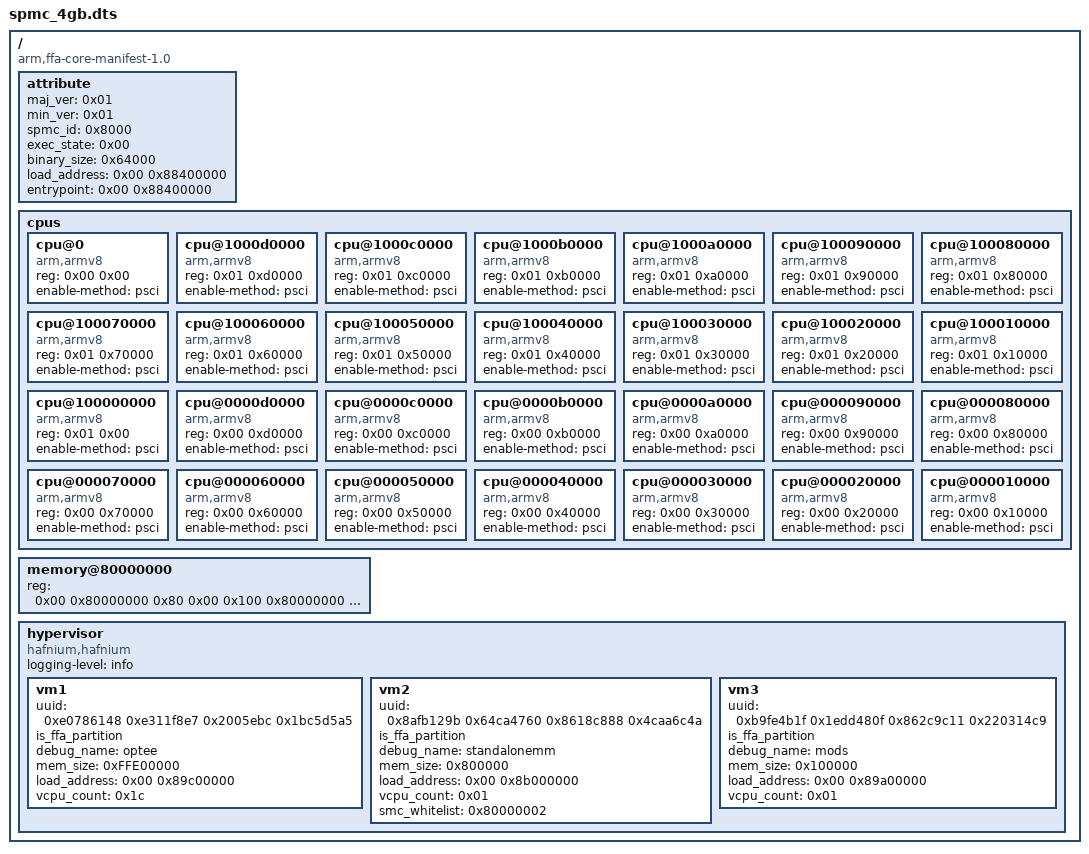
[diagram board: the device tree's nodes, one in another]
/dts-v1/;

/ {
	#size-cells = <0x02>;
	#address-cells = <0x02>;
	compatible = "arm,ffa-core-manifest-1.0";

	attribute {
		maj_ver = <0x01>;
		min_ver = <0x01>;
		spmc_id = <0x8000>;
		exec_state = <0x00>;
		binary_size = <0x64000>;
		load_address = <0x00 0x88400000>;
		entrypoint = <0x00 0x88400000>;
	};

	cpus {
		#address-cells = <0x02>;
		#size-cells = <0x00>;

		cpu@0 {
			device_type = "cpu";
			compatible = "arm,armv8";
			reg = <0x00 0x00>;
			enable-method = "psci";
		};

		cpu@1000d0000 {
			device_type = "cpu";
			compatible = "arm,armv8";
			reg = <0x01 0xd0000>;
			enable-method = "psci";
		};

		cpu@1000c0000 {
			device_type = "cpu";
			compatible = "arm,armv8";
			reg = <0x01 0xc0000>;
			enable-method = "psci";
		};

		cpu@1000b0000 {
			device_type = "cpu";
			compatible = "arm,armv8";
			reg = <0x01 0xb0000>;
			enable-method = "psci";
		};

		cpu@1000a0000 {
			device_type = "cpu";
			compatible = "arm,armv8";
			reg = <0x01 0xa0000>;
			enable-method = "psci";
		};

		cpu@100090000 {
			device_type = "cpu";
			compatible = "arm,armv8";
			reg = <0x01 0x90000>;
			enable-method = "psci";
		};

		cpu@100080000 {
			device_type = "cpu";
			compatible = "arm,armv8";
			reg = <0x01 0x80000>;
			enable-method = "psci";
		};

		cpu@100070000 {
			device_type = "cpu";
			compatible = "arm,armv8";
			reg = <0x01 0x70000>;
			enable-method = "psci";
		};

		cpu@100060000 {
			device_type = "cpu";
			compatible = "arm,armv8";
			reg = <0x01 0x60000>;
			enable-method = "psci";
		};

		cpu@100050000 {
			device_type = "cpu";
			compatible = "arm,armv8";
			reg = <0x01 0x50000>;
			enable-method = "psci";
		};

		cpu@100040000 {
			device_type = "cpu";
			compatible = "arm,armv8";
			reg = <0x01 0x40000>;
			enable-method = "psci";
		};

		cpu@100030000 {
			device_type = "cpu";
			compatible = "arm,armv8";
			reg = <0x01 0x30000>;
			enable-method = "psci";
		};

		cpu@100020000 {
			device_type = "cpu";
			compatible = "arm,armv8";
			reg = <0x01 0x20000>;
			enable-method = "psci";
		};

		cpu@100010000 {
			device_type = "cpu";
			compatible = "arm,armv8";
			reg = <0x01 0x10000>;
			enable-method = "psci";
		};

		cpu@100000000 {
			device_type = "cpu";
			compatible = "arm,armv8";
			reg = <0x01 0x00>;
			enable-method = "psci";
		};

		cpu@0000d0000 {
			device_type = "cpu";
			compatible = "arm,armv8";
			reg = <0x00 0xd0000>;
			enable-method = "psci";
		};

		cpu@0000c0000 {
			device_type = "cpu";
			compatible = "arm,armv8";
			reg = <0x00 0xc0000>;
			enable-method = "psci";
		};

		cpu@0000b0000 {
			device_type = "cpu";
			compatible = "arm,armv8";
			reg = <0x00 0xb0000>;
			enable-method = "psci";
		};

		cpu@0000a0000 {
			device_type = "cpu";
			compatible = "arm,armv8";
			reg = <0x00 0xa0000>;
			enable-method = "psci";
		};

		cpu@000090000 {
			device_type = "cpu";
			compatible = "arm,armv8";
			reg = <0x00 0x90000>;
			enable-method = "psci";
		};

		cpu@000080000 {
			device_type = "cpu";
			compatible = "arm,armv8";
			reg = <0x00 0x80000>;
			enable-method = "psci";
		};

		cpu@000070000 {
			device_type = "cpu";
			compatible = "arm,armv8";
			reg = <0x00 0x70000>;
			enable-method = "psci";
		};

		cpu@000060000 {
			device_type = "cpu";
			compatible = "arm,armv8";
			reg = <0x00 0x60000>;
			enable-method = "psci";
		};

		cpu@000050000 {
			device_type = "cpu";
			compatible = "arm,armv8";
			reg = <0x00 0x50000>;
			enable-method = "psci";
		};

		cpu@000040000 {
			device_type = "cpu";
			compatible = "arm,armv8";
			reg = <0x00 0x40000>;
			enable-method = "psci";
		};

		cpu@000030000 {
			device_type = "cpu";
			compatible = "arm,armv8";
			reg = <0x00 0x30000>;
			enable-method = "psci";
		};

		cpu@000020000 {
			device_type = "cpu";
			compatible = "arm,armv8";
			reg = <0x00 0x20000>;
			enable-method = "psci";
		};

		cpu@000010000 {
			device_type = "cpu";
			compatible = "arm,armv8";
			reg = <0x00 0x10000>;
			enable-method = "psci";
		};
	};

	memory@80000000 {
		device_type = "ns-memory";
		reg = <0x00 0x80000000 0x80 0x00 0x100 0x80000000 0x80 0x00>;
	};

	hypervisor {
		compatible = "hafnium,hafnium";
		logging-level = "info";

		vm1 {
			uuid = <0xe0786148 0xe311f8e7 0x2005ebc 0x1bc5d5a5>;
			is_ffa_partition;
			debug_name = "optee";
			mem_size = <0xFFE00000>;
			load_address = <0x00 0x89c00000>;
			vcpu_count = <0x1c>;
		};

		vm2 {
			uuid = <0x8afb129b 0x64ca4760 0x8618c888 0x4caa6c4a>;
			is_ffa_partition;
			debug_name = "standalonemm";
			mem_size = <0x800000>;
			load_address = <0x00 0x8b000000>;
			vcpu_count = <0x01>;
			smc_whitelist = <0x80000002>;
		};

		vm3 {
			uuid = <0xb9fe4b1f 0x1edd480f 0x862c9c11 0x220314c9>;
			is_ffa_partition;
			debug_name = "mods";
			mem_size = <0x100000>;
			load_address = <0x00 0x89a00000>;
			vcpu_count = <0x01>;
		};
	};
};
